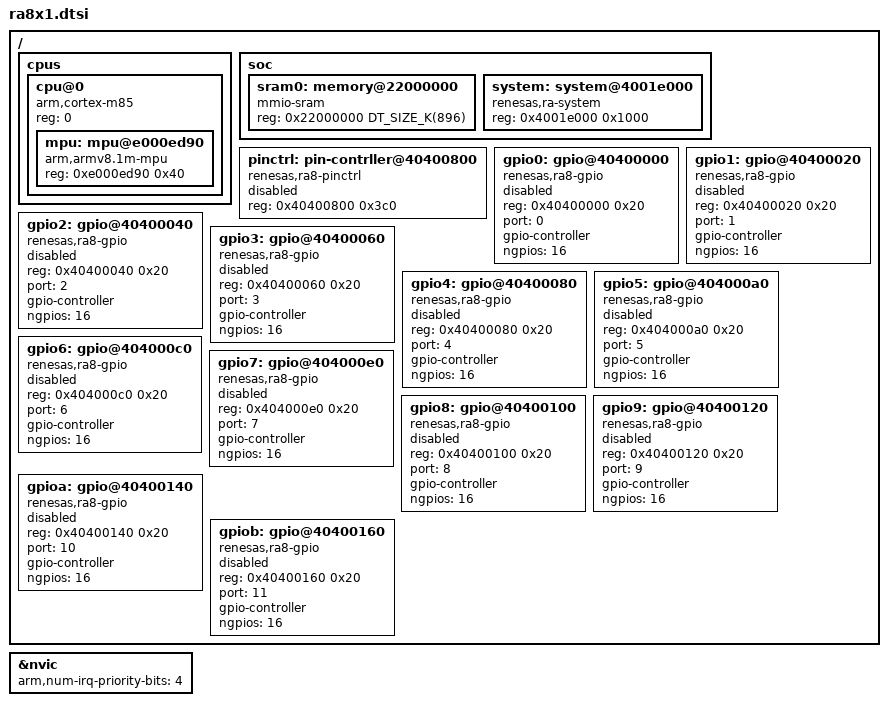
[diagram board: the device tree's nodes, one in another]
/*
 * Copyright (c) 2024 Renesas Electronics Corporation
 *
 * SPDX-License-Identifier: Apache-2.0
 */

#include <mem.h>
#include <arm/armv8.1-m.dtsi>
#include <freq.h>
#include <zephyr/dt-bindings/pinctrl/renesas/ra-pinctrl.h>


/ {
	cpus {
		#address-cells = <1>;
		#size-cells = <0>;

		cpu@0 {
			device_type = "cpu";
			compatible = "arm,cortex-m85";
			reg = <0>;
			#address-cells = <1>;
			#size-cells = <1>;

			mpu: mpu@e000ed90 {
				compatible = "arm,armv8.1m-mpu";
				reg = <0xe000ed90 0x40>;
			};
		};
	};

	soc {
		sram0: memory@22000000 {
			compatible = "mmio-sram";
			reg = <0x22000000 DT_SIZE_K(896)>;
		};

		system: system@4001e000 {
			compatible = "renesas,ra-system";
			reg = <0x4001e000 0x1000>;
			status = "okay";
		};
	};

	pinctrl: pin-contrller@40400800 {
			compatible = "renesas,ra8-pinctrl";
			reg = <0x40400800 0x3c0>;
			status = "disabled";
	};

	gpio0: gpio@40400000 {
			compatible = "renesas,ra8-gpio";
			reg = <0x40400000 0x20>;
			port = <0>;
			gpio-controller;
			#gpio-cells = <2>;
			ngpios = <16>;
			status = "disabled";
	};

	gpio1: gpio@40400020 {
		compatible = "renesas,ra8-gpio";
		reg = <0x40400020 0x20>;
		port = <1>;
		gpio-controller;
		#gpio-cells = <2>;
		ngpios = <16>;
		status = "disabled";
	};

	gpio2: gpio@40400040 {
		compatible = "renesas,ra8-gpio";
		reg = <0x40400040 0x20>;
		port = <2>;
		gpio-controller;
		#gpio-cells = <2>;
		ngpios = <16>;
		status = "disabled";
	};

	gpio3: gpio@40400060 {
		compatible = "renesas,ra8-gpio";
		reg = <0x40400060 0x20>;
		port = <3>;
		gpio-controller;
		#gpio-cells = <2>;
		ngpios = <16>;
		status = "disabled";
	};

	gpio4: gpio@40400080 {
		compatible = "renesas,ra8-gpio";
		reg = <0x40400080 0x20>;
		port = <4>;
		gpio-controller;
		#gpio-cells = <2>;
		ngpios = <16>;
		status = "disabled";
	};

	gpio5: gpio@404000a0 {
		compatible = "renesas,ra8-gpio";
		reg = <0x404000a0 0x20>;
		port = <5>;
		gpio-controller;
		#gpio-cells = <2>;
		ngpios = <16>;
		status = "disabled";
	};

	gpio6: gpio@404000c0 {
		compatible = "renesas,ra8-gpio";
		reg = <0x404000c0 0x20>;
		port = <6>;
		gpio-controller;
		#gpio-cells = <2>;
		ngpios = <16>;
		status = "disabled";
	};

	gpio7: gpio@404000e0 {
		compatible = "renesas,ra8-gpio";
		reg = <0x404000e0 0x20>;
		port = <7>;
		gpio-controller;
		#gpio-cells = <2>;
		ngpios = <16>;
		status = "disabled";
	};

	gpio8: gpio@40400100 {
		compatible = "renesas,ra8-gpio";
		reg = <0x40400100 0x20>;
		port = <8>;
		gpio-controller;
		#gpio-cells = <2>;
		ngpios = <16>;
		status = "disabled";
	};

	gpio9: gpio@40400120 {
		compatible = "renesas,ra8-gpio";
		reg = <0x40400120 0x20>;
		port = <9>;
		gpio-controller;
		#gpio-cells = <2>;
		ngpios = <16>;
		status = "disabled";
	};

	gpioa: gpio@40400140 {
		compatible = "renesas,ra8-gpio";
		reg = <0x40400140 0x20>;
		port = <10>;
		gpio-controller;
		#gpio-cells = <2>;
		ngpios = <16>;
		status = "disabled";
	};

	gpiob: gpio@40400160 {
		compatible = "renesas,ra8-gpio";
		reg = <0x40400160 0x20>;
		port = <11>;
		gpio-controller;
		#gpio-cells = <2>;
		ngpios = <16>;
		status = "disabled";
	};
};

&nvic {
	arm,num-irq-priority-bits = <4>;
};
